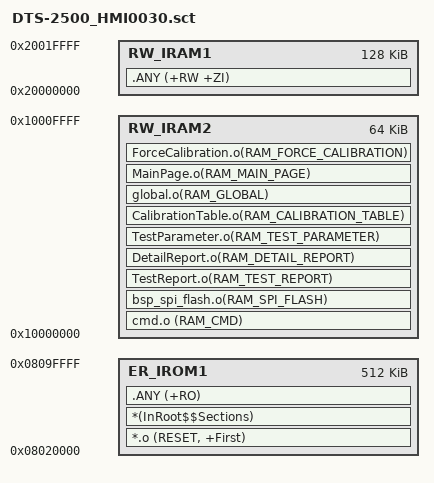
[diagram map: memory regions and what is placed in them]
; *************************************************************
; *** Scatter-Loading Description File generated by uVision ***
; *************************************************************

LR_IROM1 0x08020000 0x00080000  {    ; load region size_region
  ER_IROM1 0x08020000 0x00080000  {  ; load address = execution address
   *.o (RESET, +First)
   *(InRoot$$Sections)
   .ANY (+RO)
  }
  RW_IRAM1 0x20000000 0x00020000  {  ; RW data
   .ANY (+RW +ZI)
  }
  RW_IRAM2 0x10000000 0x00010000  {  ; RW data
   cmd.o (RAM_CMD)
   bsp_spi_flash.o(RAM_SPI_FLASH)
   TestReport.o(RAM_TEST_REPORT)
   DetailReport.o(RAM_DETAIL_REPORT)
   TestParameter.o(RAM_TEST_PARAMETER)
   CalibrationTable.o(RAM_CALIBRATION_TABLE)
   global.o(RAM_GLOBAL)
   MainPage.o(RAM_MAIN_PAGE)
   ForceCalibration.o(RAM_FORCE_CALIBRATION)
  } 
}

